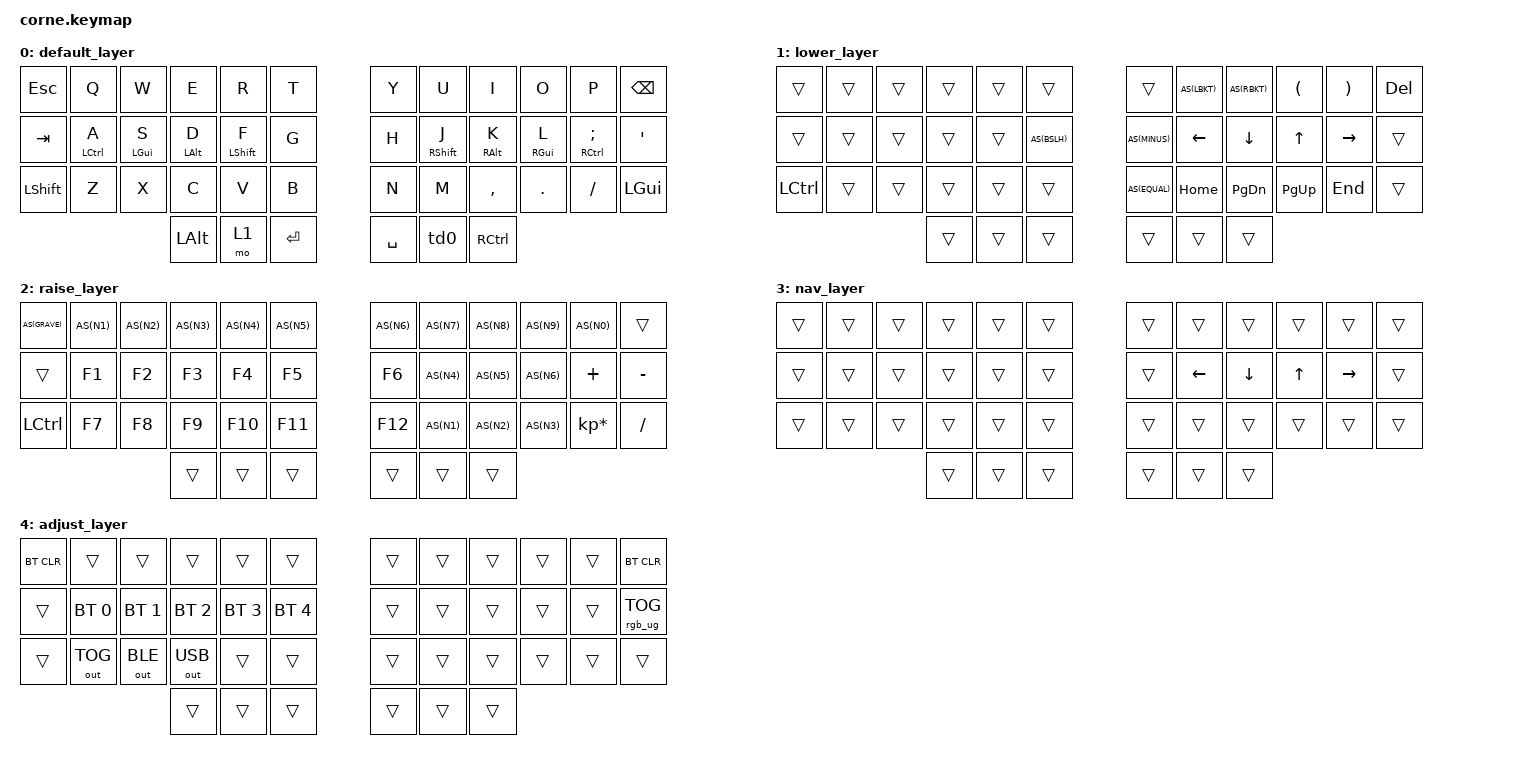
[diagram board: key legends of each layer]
/*
 * Copyright (c) 2020 The ZMK Contributors
 *
 * SPDX-License-Identifier: MIT
 */

#include <behaviors.dtsi>
#include <dt-bindings/zmk/keys.h>
#include <dt-bindings/zmk/bt.h>
#include <dt-bindings/zmk/rgb.h>
#include <dt-bindings/zmk/outputs.h>

#define AS(keycode) &as LS(keycode) keycode

/ {
  conditional_layers {
    compatible = "zmk,conditional-layers";
    tri_layer {
      if-layers = <1 2>;
      then-layer = <4>;
    };
  };
};

/ {
  behaviors {
    as: auto_shift {
      compatible = "zmk,behavior-hold-tap";
      label = "AUTO_SHIFT";
      #binding-cells = <2>;
      tapping_term_ms = <175>;
      quick_tap_ms = <0>;
      flavor = "tap-preferred";
      bindings = <&kp>, <&kp>;
    };

    hm: homerow_mods {
      compatible = "zmk,behavior-hold-tap";
      label = "HOMEROW_MODS";
      #binding-cells = <2>;
      tapping-term-ms = <150>;
      quick-tap-ms = <0>;
      flavor = "tap-preferred";
      bindings = <&kp>, <&kp>;
    };

    td0: tap_dance_0 {
      compatible = "zmk,behavior-tap-dance";
      label = "TAP_DANCE_0";
      #binding-cells = <0>;
      tapping-term-ms = <200>;
      bindings = <&mo 2>, <&mo 3>;
    };

    // mt: behavior_mod_tap {
		// 	compatible = "zmk,behavior-hold-tap";
		// 	label = "MOD_TAP";
		// 	#binding-cells = <2>;
		// 	flavor = "hold-preferred";
		// 	tapping-term-ms = <175>;
		// 	bindings = <&kp>, <&kp>;
		// };
  };

  keymap {
    compatible = "zmk,keymap";

    default_layer {
      // -----------------------------------------------------------------------------------------
      // | ESC  |  Q  |  W  |  E  |  R  |  T  |   |  Y  |  U  |  I   |  O  |  P  | BKSP |
      // | TAB  |  A  |  S  |  D  |  F  |  G  |   |  H  |  J  |  K   |  L  |  ;  |  '   |
      // | SHFT |  Z  |  X  |  C  |  V  |  B  |   |  N  |  M  |  ,   |  .  |  /  | GUI  |
      //                    | ALT | LWR | ENT |   | SPC | RSE | CTRL |
      bindings = <
        &kp ESC   &kp Q       &kp W      &kp E      &kp R          &kp T     &kp Y &kp U       &kp I      &kp O      &kp P         &kp BSPC
        &kp TAB   &hm LCTRL A &hm LGUI S &hm LALT D &hm LSHFT F    &kp G     &kp H &hm RSHFT J &hm RALT K &hm RGUI L &hm RCTL SEMI &kp SQT
        &kp LSHFT &kp Z       &kp X      &kp C      &kp V          &kp B     &kp N &kp M       &kp COMMA  &kp DOT    &kp FSLH      &kp LGUI
                              &kp LALT   &mo 1      &kp RET        &kp SPACE &td0  &kp RCTRL
      >;
    };

    lower_layer {
      // -----------------------------------------------------------------------------------------
      // |      |     |     |     |     |     |   | *EM*| [{  | ]}  |  (  |  )  | DEL  |
      // |      |     |     |     |     |  \| |   | -_  | LFT | DWN |  UP | RGT |      |
      // | CTRL |     |     |     |     |     |   | =+  |HOME |PGDN |PGUP | END |      | // TODO: Fix this row when &mkp is committed
      //                    |     |     |     |   |     |     |     |
      bindings = <
        &trans    &trans &trans  &trans &trans &trans      &trans    AS(LBKT) AS(RBKT)  &kp LPAR  &kp RPAR  &kp DEL
        &trans    &trans &trans  &trans &trans AS(BSLH)    AS(MINUS) &kp LEFT &kp DOWN  &kp UP    &kp RIGHT &trans
        &kp LCTRL &trans &trans  &trans &trans &trans      AS(EQUAL) &kp HOME &kp PG_DN &kp PG_UP &kp END   &trans
                                 &trans &trans &trans      &trans    &trans   &trans
      >;
    };

    raise_layer {
      // -----------------------------------------------------------------------------------------
      // |  `   |  1  |  2  |  3  |  4  |  5  |   |  6  |  7  |  8  |  9  |  0  |      |
      // |      | F1  | F2  | F3  | F4  | F5  |   | F6  |  4  |  5  |  6  |  +  |  -   |
      // | CTRL | F7  | F8  | F9  | F10 | F11 |   | F12 |  1  |  2  |  3  |  *  |  /   |
      //                    |     |     |     |   |     |     |     |
      bindings = <
        AS(GRAVE) AS(N1) AS(N2) AS(N3) AS(N4)  AS(N5)    AS(N6)  AS(N7) AS(N8) AS(N9) AS(N0)          &trans
        &trans    &kp F1 &kp F2 &kp F3 &kp F4  &kp F5    &kp F6  AS(N4) AS(N5) AS(N6) &kp PLUS        &kp MINUS
        &kp LCTRL &kp F7 &kp F8 &kp F9 &kp F10 &kp F11   &kp F12 AS(N1) AS(N2) AS(N3) &kp KP_MULTIPLY &kp FSLH
                                &trans &trans  &trans    &trans  &trans &trans
      >;
    };

    nav_layer {
      // -----------------------------------------------------------------------------------------
      // |      |     |     |     |     |     |   |     |     |     |     |     |      |
      // |      |     |     |     |     |     |   |     | LFT | DWN |  UP | RGT |      |
      // |      |     |     |     |     |     |   |     |     |     |     |     |      |
      //                    |     |     |     |   |     |     |     |
      bindings = <
        &trans &trans &trans &trans &trans &trans    &trans &trans   &trans   &trans &trans    &trans
        &trans &trans &trans &trans &trans &trans    &trans &kp LEFT &kp DOWN &kp UP &kp RIGHT &trans
        &trans &trans &trans &trans &trans &trans    &trans &trans   &trans   &trans &trans    &trans
                             &trans &trans &trans    &trans &trans   &trans
      >;
    };

    adjust_layer {
      // -----------------------------------------------------------------------------------------
      // |BTCLR|     |     |     |     |     |   |     |     |     |     |     |BTCLR |
      // |     | BT1 | BT2 | BT3 | BT4 | BT5 |   |     |     |     |     |     |RGBT  |
      // |     | OTG | BLE | USB |     |     |   |     |     |     |     |     |      |
      //                   |     |     |     |   |     |     |     |
      bindings = <
        &bt BT_CLR &trans       &trans       &trans       &trans       &trans          &trans &trans &trans &trans &trans &bt BT_CLR
        &trans     &bt BT_SEL 0 &bt BT_SEL 1 &bt BT_SEL 2 &bt BT_SEL 3 &bt BT_SEL 4    &trans &trans &trans &trans &trans &rgb_ug RGB_TOG
        &trans     &out OUT_TOG &out OUT_BLE &out OUT_USB &trans       &trans          &trans &trans &trans &trans &trans &trans
                                             &trans       &trans       &trans          &trans &trans &trans
      >;
    };
  };
};
